# APM32F446 register map
File version: 1.0
CPU: CM4 r0p1, little endian, MPU, FPU, 4 interrupt priority bits
Registers are 32-bit, read-write, reset 0x0 unless marked. A register's access mark holds for its fields unless they carry their own. Offsets are from the block's base; [hi:lo] are bit positions; {n}, {i} and the like mark numbered series; 'fields as' and 'values as' point back to an identical list.

## LPITMR — Low Power Periodic Interrupt Timer
Base 0x40037000
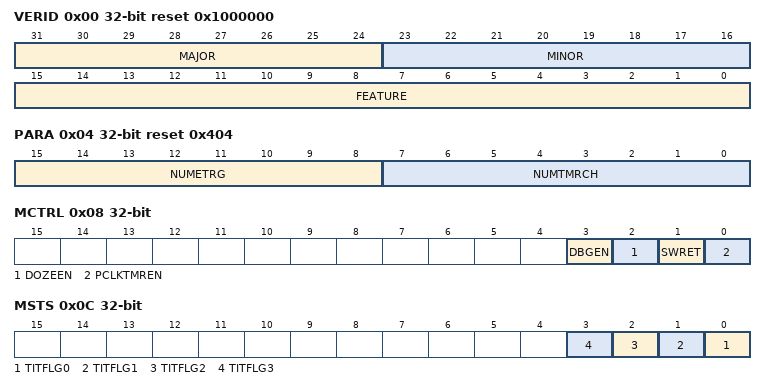
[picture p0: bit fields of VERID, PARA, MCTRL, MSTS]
0x00 VERID ro reset 0x1000000 — Version ID Register
  [31:24] MAJOR — Major Version Number
  [23:16] MINOR — Minor Version Number
  [15:0] FEATURE — Feature Support Number
0x04 PARA ro reset 0x404 — Parameter Register
  [15:8] NUMETRG — Number of External Triggers
  [7:0] NUMTMRCH — Number of Timer Channels
0x08 MCTRL — Module Control Register
  [3] DBGEN — Enable timer channels run in Debug Mode
    0=Timer channels are stopped in Debug mode; 1=Timer channels continue to run in Debug mode
  [2] DOZEEN — Enable timer channels run in doze mode
    0=Timer channels are stopped in DOZE mode; 1=Timer channels continue to run in DOZE mode
  [1] SWRET — Software Reset
    0=Timer channels and registers are not reset; 1=Timer channels and registers are reset
  [0] PCLKTMREN — Peripheral Clock Timer Enable
    0=Peripheral clock to timers is disabled; 1=Peripheral clock to timers is enabled
0x0C MSTS — Module Status Register
  [all] fields
    0=Timer has not timed out; 1=Timeout has occurred
  [n] TITFLG{n} (n=0..3) — Channel {n} Timer Interrupt Timeout Flag
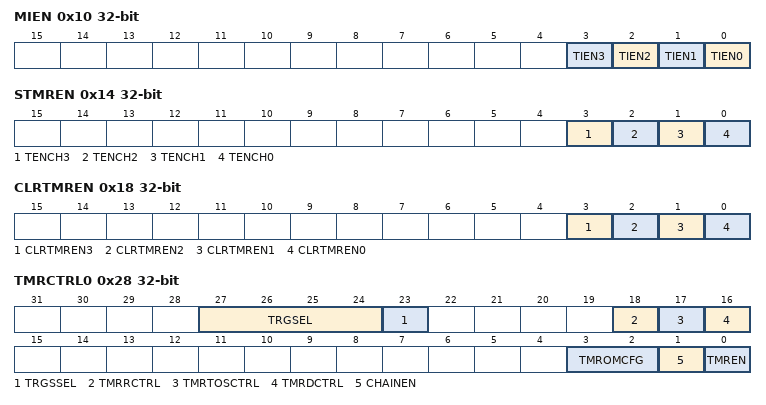
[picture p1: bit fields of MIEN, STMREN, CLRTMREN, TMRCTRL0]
0x10 MIEN — Module Interrupt Enable Register
  [all] fields
    0=Interrupt generation is disabled; 1=Interrupt generation is enabled
  [n] TIEN{n} (n=0..3) — Channel {n} Timer Interrupt Enable
0x14 STMREN — Set Timer Enable Register
  [3] TENCH3 — Timer Channel 3 Enable
    0=No effect; 1=Enables the Timer Channel 3
  [2] TENCH2 — Timer Channel 2 Enable
    0=No Effect; 1=Enables the Timer Channel 2
  [1] TENCH1 — Timer Channel 1 Enable
    0=No Effect; 1=Enables the Timer Channel 1
  [0] TENCH0 — Timer Channel 0 Enable
    0=No effect; 1=Enables the Timer Channel 0
0x18 CLRTMREN — Clear Timer Enable Register
  [3] CLRTMREN3 wo — Clear Timer Channel 3 Enable
    0=No Action; 1=Clear T_EN bit for Timer Channel 3
  [2] CLRTMREN2 wo — Clear Timer Channel 2 Enable
    0=No Action; 1=Clear T_EN bit for Timer Channel 2
  [1] CLRTMREN1 wo — Clear Timer Channel 1 Enable
    0=No Action; 1=Clear T_EN bit for Timer Channel 1
  [0] CLRTMREN0 wo — Clear Timer Channel 0 Enable
    0=No action; 1=Clear T_EN bit for Timer Channel 0
{0x20+0x10*i} TMRV{i} (i=0..3) — Timer Value Register {i}
  [31:0] TMRV — Timer Value
    0=Invalid load value in compare modes; 1=Invalid load value in compare modes
{0x24+0x10*i} CTMRV{i} ro reset 0xFFFFFFFF (i=0..3) — Current Timer Value {i}
  [31:0] CTMRV — Current Timer Value
0x28 TMRCTRL0 — Timer Control Register 0
  [27:24] TRGSEL — Trigger Select
  [23] TRGSSEL — Trigger Source Select
    0=Trigger source selected in external; 1=Trigger source selected is the internal trigger
  [18] TMRRCTRL — Timer Reload Control
    0=Timer will not reload on selected trigger; 1=Timer will reload on selected trigger
  [17] TMRTOSCTRL — Timer Timeout Stop Control
    0=The channel timer does not stop after timeout; 1=The channel timer will stop after a timeout, and the channel timer will restart based on TMRDCTRL. When TMRDCTRL = 0, the channel timer will restart after a rising edge on the T_EN bit is detected (which means that the timer channel is disabled and then enabled); when TMRDCTRL = 1, the channel timer will restart after a rising edge on the selected trigger is detected.
  [16] TMRDCTRL — Timer Decrement Control
    0=Timer starts to decrement immediately based on restart condition (controlled by TMRTOSCTRL bit); 1=Timer starts to decrement when rising edge on selected trigger is detected
  [3:2] TMROMCFG — Timer Operation Mode Configure
    0=32-bit Periodic Counter; 1=Dual 16-bit Periodic Counter; 2=32-bit Trigger Accumulator; 3=32-bit Trigger Input Capture
  [1] CHAINEN — Channel Chain Enable
    0=Channel Chaining is disabled. Channel Timer runs independently.; 1=Channel Chaining is enabled. Timer decrements on previous channel's timeout
  [0] TMREN — Timer Channel Enable
    0=Timer Channel is disabled; 1=Timer Channel is enabled
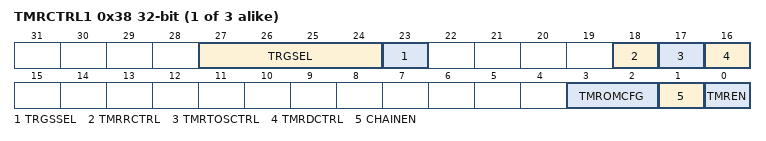
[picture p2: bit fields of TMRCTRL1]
{0x28+0x10*i} TMRCTRL{i} (i=1..3) — Timer Control Register {i}
  [27:24] TRGSEL — Trigger Select
  [23] TRGSSEL — Trigger Source Select
    values as TMRCTRL0.TRGSSEL
  [18] TMRRCTRL — Timer Reload Control
    values as TMRCTRL0.TMRRCTRL
  [17] TMRTOSCTRL — Timer Timeout Stop Control
    values as TMRCTRL0.TMRTOSCTRL
  [16] TMRDCTRL — Timer Decrement Control
    values as TMRCTRL0.TMRDCTRL
  [3:2] TMROMCFG — Timer Operation Mode Configure
    values as TMRCTRL0.TMROMCFG
  [1] CHAINEN — Chain Channel Enable
    values as TMRCTRL0.CHAINEN
  [0] TMREN — Timer Channel Enable
    0=Timer Channel is disabled; 1=Timer Channel is enabled
